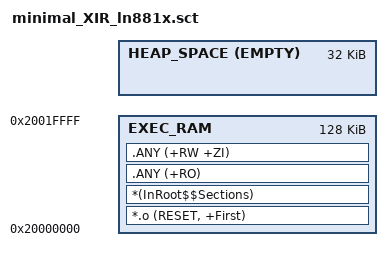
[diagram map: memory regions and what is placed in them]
#! armcc -E

LOAD_RAM 0x20000000 0x00020000  {    ; load region size_region
  EXEC_RAM 0x20000000 0x00020000{  ; load address = execution address
	  *.o (RESET, +First);
	  *(InRoot$$Sections);
	  .ANY (+RO);
	  .ANY (+RW +ZI);
  }

  HEAP_SPACE +0 EMPTY 0x8000 ; Heap region growing up
  { }
}

	

